VERSION ""

NS_ :

BS_:

BU_: ESC Master

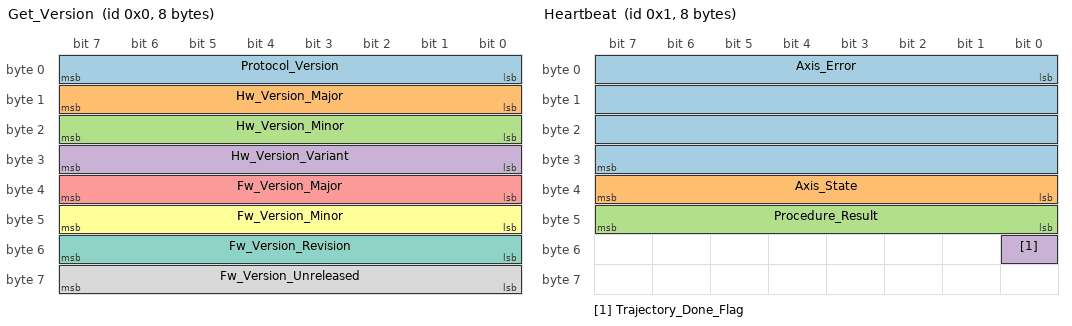
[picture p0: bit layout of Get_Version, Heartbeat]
BO_ 0 Get_Version: 8 ESC
 SG_ Protocol_Version : 0|8@1+ (1,0) [0|0] "" Master
 SG_ Hw_Version_Major : 8|8@1+ (1,0) [0|0] "" Master
 SG_ Hw_Version_Minor : 16|8@1+ (1,0) [0|0] "" Master
 SG_ Hw_Version_Variant : 24|8@1+ (1,0) [0|0] "" Master
 SG_ Fw_Version_Major : 32|8@1+ (1,0) [0|0] "" Master
 SG_ Fw_Version_Minor : 40|8@1+ (1,0) [0|0] "" Master
 SG_ Fw_Version_Revision : 48|8@1+ (1,0) [0|0] "" Master
 SG_ Fw_Version_Unreleased : 56|8@1+ (1,0) [0|0] "" Master

BO_ 1 Heartbeat: 8 ESC
 SG_ Axis_Error : 0|32@1+ (1,0) [0|0] "" Master
 SG_ Axis_State : 32|8@1+ (1,0) [0|0] "" Master
 SG_ Procedure_Result : 40|8@1+ (1,0) [0|0] "" Master
 SG_ Trajectory_Done_Flag : 48|1@1+ (1,0) [0|0] "" Master

BO_ 2 Estop: 0 Master

BO_ 3 Get_Error: 8 ESC
 SG_ Active_Errors : 0|32@1+ (1,0) [0|0] "" Master
 SG_ Disarm_Reason : 32|32@1+ (1,0) [0|0] "" Master

BO_ 6 Set_Axis_Node_ID: 4 Master
 SG_ Axis_Node_ID : 0|32@1+ (1,0) [0|0] "" ESC

BO_ 7 Set_Axis_State: 4 Master
 SG_ Axis_Requested_State : 0|32@1+ (1,0) [0|0] "" ESC

BO_ 9 Get_Encoder_Estimates: 8 ESC
 SG_ Pos_Estimate : 0|32@1- (1,0) [0|0] "rev" Master
 SG_ Vel_Estimate : 32|32@1- (1,0) [0|0] "rev/s" Master

BO_ 11 Set_Controller_Mode: 8 Master
 SG_ Control_Mode : 0|32@1+ (1,0) [0|0] "" ESC
 SG_ Input_Mode : 32|32@1+ (1,0) [0|0] "" ESC

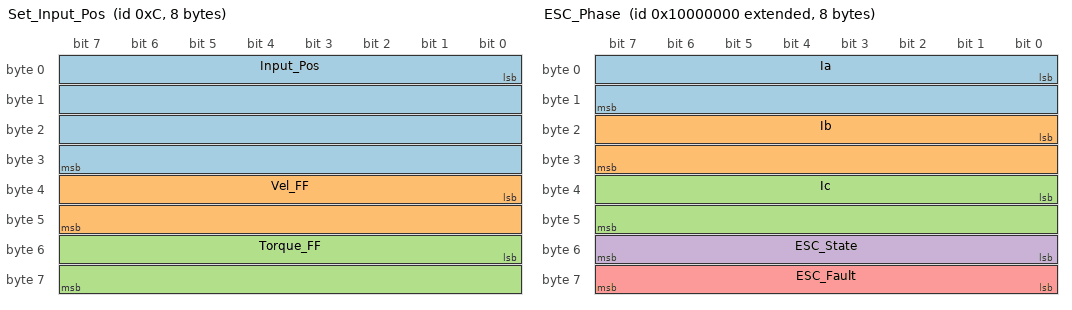
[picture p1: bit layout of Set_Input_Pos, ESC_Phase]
BO_ 12 Set_Input_Pos: 8 Master
 SG_ Input_Pos : 0|32@1- (1,0) [0|0] "rev" ESC
 SG_ Vel_FF : 32|16@1- (0.001,0) [0|0] "rev/s" ESC
 SG_ Torque_FF : 48|16@1- (0.001,0) [0|0] "Nm" ESC

BO_ 13 Set_Input_Vel: 8 Master
 SG_ Input_Vel : 0|32@1- (1,0) [0|0] "rev/s" ESC
 SG_ Input_Torque_FF : 32|32@1- (1,0) [0|0] "Nm" ESC

BO_ 14 Set_Input_Torque: 4 Master
 SG_ Input_Torque : 0|32@1- (1,0) [0|0] "Nm" ESC

BO_ 15 Set_Limits: 8 Master
 SG_ Velocity_Limit : 0|32@1- (1,0) [0|0] "rev/s" ESC
 SG_ Current_Limit : 32|32@1- (1,0) [0|0] "A" ESC

BO_ 17 Set_Traj_Vel_Limit: 4 Master
 SG_ Traj_Vel_Limit : 0|32@1- (1,0) [0|0] "rev/s" ESC

BO_ 18 Set_Traj_Accel_Limits: 8 Master
 SG_ Traj_Accel_Limit : 0|32@1- (1,0) [0|0] "rev/s^2" ESC
 SG_ Traj_Decel_Limit : 32|32@1- (1,0) [0|0] "rev/s^2" ESC

BO_ 19 Set_Traj_Inertia: 4 Master
 SG_ Traj_Inertia : 0|32@1- (1,0) [0|0] "Nm/(rev/s^2)" ESC

BO_ 20 Get_Iq: 8 ESC
 SG_ Iq_Setpoint : 0|32@1- (1,0) [0|0] "A" Master
 SG_ Iq_Measured : 32|32@1- (1,0) [0|0] "A" Master

BO_ 21 Get_Temperature: 8 ESC
 SG_ FET_Temperature : 0|32@1- (1,0) [0|0] "degC" Master
 SG_ Motor_Temperature : 32|32@1- (1,0) [0|0] "degC" Master

BO_ 22 Reboot: 1 Master
 SG_ Action : 0|8@1+ (1,0) [0|0] "" ESC

BO_ 23 Get_Bus_Voltage_Current: 8 ESC
 SG_ Bus_Voltage : 0|32@1- (1,0) [0|0] "V" Master
 SG_ Bus_Current : 32|32@1- (1,0) [0|0] "A" Master

BO_ 24 Clear_Errors: 1 Master
 SG_ Identify : 0|8@1+ (1,0) [0|0] "" ESC

BO_ 25 Set_Absolute_Position: 4 Master
 SG_ Position : 0|32@1- (1,0) [0|0] "rev" ESC

BO_ 26 Set_Pos_Gain: 4 Master
 SG_ Pos_Gain : 0|32@1- (1,0) [0|0] "(rev/s)/rev" ESC

BO_ 27 Set_Vel_Gains: 8 Master
 SG_ Vel_Gain : 0|32@1- (1,0) [0|0] "Nm/(rev/s)" ESC
 SG_ Vel_Integrator_Gain : 32|32@1- (1,0) [0|0] "Nm/rev" ESC

BO_ 28 Get_Torques: 8 ESC
 SG_ Torque_Target : 0|32@1- (1,0) [0|0] "Nm" Master
 SG_ Torque_Estimate : 32|32@1- (1,0) [0|0] "Nm" Master

BO_ 29 Get_Powers: 8 ESC
 SG_ Electrical_Power : 0|32@1- (1,0) [0|0] "W" Master
 SG_ Mechanical_Power : 32|32@1- (1,0) [0|0] "W" Master

BO_ 2415919104 ESC_Phase: 8 ESC
 SG_ Ia : 0|16@1- (0.01,0) [0|0] "A" Master
 SG_ Ib : 16|16@1- (0.01,0) [0|0] "A" Master
 SG_ Ic : 32|16@1- (0.01,0) [0|0] "A" Master
 SG_ ESC_State : 48|8@1+ (1,0) [0|0] "" Master
 SG_ ESC_Fault : 56|8@1+ (1,0) [0|0] "" Master

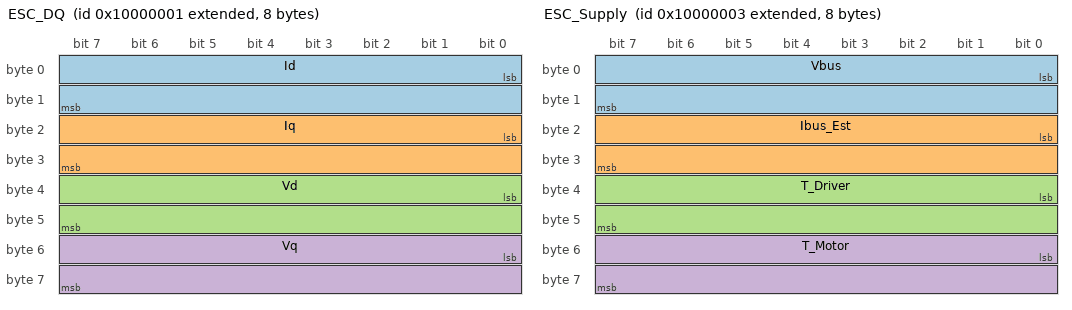
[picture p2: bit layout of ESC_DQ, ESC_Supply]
BO_ 2415919105 ESC_DQ: 8 ESC
 SG_ Id : 0|16@1- (0.01,0) [0|0] "A" Master
 SG_ Iq : 16|16@1- (0.01,0) [0|0] "A" Master
 SG_ Vd : 32|16@1- (0.01,0) [0|0] "V" Master
 SG_ Vq : 48|16@1- (0.01,0) [0|0] "V" Master

BO_ 2415919106 ESC_Motion: 8 ESC
 SG_ Speed : 0|32@1- (1,0) [0|0] "rpm" Master
 SG_ Speed_Cmd : 32|32@1- (1,0) [0|0] "rpm" Master

BO_ 2415919107 ESC_Supply: 8 ESC
 SG_ Vbus : 0|16@1+ (0.001,0) [0|0] "V" Master
 SG_ Ibus_Est : 16|16@1- (0.01,0) [0|0] "A" Master
 SG_ T_Driver : 32|16@1- (0.1,0) [0|0] "degC" Master
 SG_ T_Motor : 48|16@1- (0.1,0) [0|0] "degC" Master

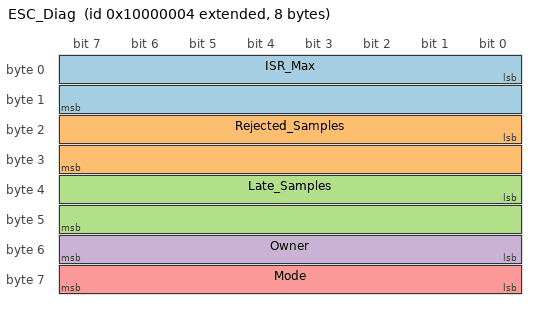
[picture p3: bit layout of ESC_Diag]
BO_ 2415919108 ESC_Diag: 8 ESC
 SG_ ISR_Max : 0|16@1+ (0.1,0) [0|0] "us" Master
 SG_ Rejected_Samples : 16|16@1+ (1,0) [0|0] "" Master
 SG_ Late_Samples : 32|16@1+ (1,0) [0|0] "" Master
 SG_ Owner : 48|8@1+ (1,0) [0|0] "" Master
 SG_ Mode : 56|8@1+ (1,0) [0|0] "" Master

CM_ "ESC with ODrive CANSimple protocol (v0.6 layout). Extra 29-bit frames 0x10000000 | node << 8 | index. Generated by can/make_dbc.py";
SIG_VALTYPE_ 9 Pos_Estimate : 1;
SIG_VALTYPE_ 9 Vel_Estimate : 1;
SIG_VALTYPE_ 12 Input_Pos : 1;
SIG_VALTYPE_ 13 Input_Vel : 1;
SIG_VALTYPE_ 13 Input_Torque_FF : 1;
SIG_VALTYPE_ 14 Input_Torque : 1;
SIG_VALTYPE_ 15 Velocity_Limit : 1;
SIG_VALTYPE_ 15 Current_Limit : 1;
SIG_VALTYPE_ 17 Traj_Vel_Limit : 1;
SIG_VALTYPE_ 18 Traj_Accel_Limit : 1;
SIG_VALTYPE_ 18 Traj_Decel_Limit : 1;
SIG_VALTYPE_ 19 Traj_Inertia : 1;
SIG_VALTYPE_ 20 Iq_Setpoint : 1;
SIG_VALTYPE_ 20 Iq_Measured : 1;
SIG_VALTYPE_ 21 FET_Temperature : 1;
SIG_VALTYPE_ 21 Motor_Temperature : 1;
SIG_VALTYPE_ 23 Bus_Voltage : 1;
SIG_VALTYPE_ 23 Bus_Current : 1;
SIG_VALTYPE_ 25 Position : 1;
SIG_VALTYPE_ 26 Pos_Gain : 1;
SIG_VALTYPE_ 27 Vel_Gain : 1;
SIG_VALTYPE_ 27 Vel_Integrator_Gain : 1;
SIG_VALTYPE_ 28 Torque_Target : 1;
SIG_VALTYPE_ 28 Torque_Estimate : 1;
SIG_VALTYPE_ 29 Electrical_Power : 1;
SIG_VALTYPE_ 29 Mechanical_Power : 1;
SIG_VALTYPE_ 2415919106 Speed : 1;
SIG_VALTYPE_ 2415919106 Speed_Cmd : 1;
VAL_ 1 Axis_State 1 "IDLE" 3 "FULL_CALIBRATION_SEQUENCE" 8 "CLOSED_LOOP_CONTROL" 9 "LOCKIN_SPIN" ;
VAL_ 1 Procedure_Result 0 "SUCCESS" 1 "BUSY" 2 "CANCELLED" 3 "DISARMED" 5 "POLE_PAIR_CPR_MISMATCH" 6 "PHASE_RESISTANCE_OUT_OF_RANGE" 7 "PHASE_INDUCTANCE_OUT_OF_RANGE" 15 "NOT_CONVERGING" ;
VAL_ 7 Axis_Requested_State 1 "IDLE" 3 "FULL_CALIBRATION_SEQUENCE" 4 "MOTOR_CALIBRATION" 7 "ENCODER_OFFSET_CALIBRATION" 8 "CLOSED_LOOP_CONTROL" 9 "LOCKIN_SPIN" ;
VAL_ 11 Control_Mode 0 "VOLTAGE_CONTROL" 1 "TORQUE_CONTROL" 2 "VELOCITY_CONTROL" 3 "POSITION_CONTROL" ;
VAL_ 11 Input_Mode 0 "INACTIVE" 1 "PASSTHROUGH" 2 "VEL_RAMP" 3 "POS_FILTER" 5 "TRAP_TRAJ" 6 "TORQUE_RAMP" ;
VAL_ 22 Action 0 "REBOOT" 1 "SAVE_CONFIGURATION" ;
VAL_ 2415919104 ESC_State 0 "IDLE" 1 "PRECHARGE" 2 "ALIGN" 3 "RUN" 4 "FAULT" 5 "CALIB" ;
VAL_ 2415919104 ESC_Fault 0 "none" 1 "overcurrent" 2 "overvoltage" 3 "undervoltage" 4 "overtemp" 5 "encoder" 6 "overspeed" 7 "estop" 8 "CAN_timeout" ;
VAL_ 2415919108 Owner 0 "none" 1 "USB" 2 "CAN" ;
VAL_ 2415919108 Mode 0 "open_loop" 1 "torque" 2 "speed" 3 "position" ;
